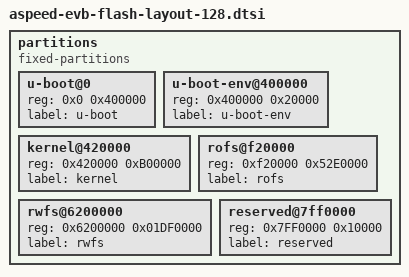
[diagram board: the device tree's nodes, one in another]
// SPDX-License-Identifier: GPL-2.0+

partitions {
	compatible = "fixed-partitions";
	#address-cells = <1>;
	#size-cells = <1>;

	u-boot@0 {
		reg = <0x0 0x400000>; // 4MB
		label = "u-boot";
	};

	u-boot-env@400000 {
		reg = <0x400000 0x20000>; // 128KB
		label = "u-boot-env";
	};

	kernel@420000 {
		reg = <0x420000 0xB00000>; // 9MB
		label = "kernel";
	};

	rofs@f20000 {
		reg = <0xf20000 0x52E0000>; // 82.875MB
		label = "rofs";
	};

	rwfs@6200000 {
               reg = <0x6200000 0x01DF0000>; // 29.8125MB
               label = "rwfs";
        };

        reserved@7ff0000 {
                reg = <0x7FF0000 0x10000>; // 64KB reserved
                label = "reserved";
        };
};
